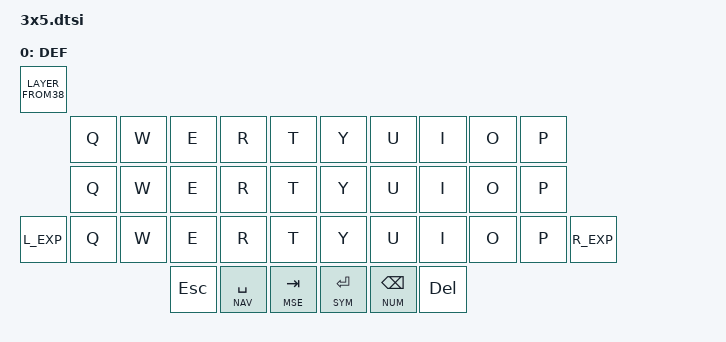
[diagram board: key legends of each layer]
#include <behaviors.dtsi>
#include <dt-bindings/zmk/keys.h>
#include <dt-bindings/zmk/bt.h>
// #include <dt-bindings/zmk/outputs.h>
// #include <dt-bindings/zmk/rgb.h>
// #include <dt-bindings/zmk/ext_power.h>
#include <behaviors/rgbled_widget.dtsi>

// Layer aliases
#define DEF 0
// #define NUM 1
// #define SYM 2
// #define NAV 3
// #define MSE 4

// totem 4 row additional keys
#define L_EXP ESC
#define R_EXP RET

// #include "shortcut.dtsi"
// #include "combos.dtsi"
// #include "mouse.dtsi"
// #include "behaviors.dtsi"
// #include "macros.dtsi"
/ {
    keymap {
        compatible = "zmk,keymap";

        default_layer {
            display-name = "DEF";
            bindings = <LAYER_FROM38( \
//           ╭──────────────┬──────────────┬──────────────┬──────────────┬──────────────╮   ╭──────────────┬──────────────┬──────────────┬──────────────┬──────────────╮
              &kp Q,         &kp W,         &kp E,         &kp R,         &kp T,             &kp Y,         &kp U,         &kp I,         &kp O,         &kp P, \
              &kp Q,         &kp W,         &kp E,         &kp R,         &kp T,             &kp Y,         &kp U,         &kp I,         &kp O,         &kp P, \
&kp L_EXP,    &kp Q,         &kp W,         &kp E,         &kp R,         &kp T,             &kp Y,         &kp U,         &kp I,         &kp O,         &kp P,         &kp R_EXP, \
                                            &kp ESC,       &lt NAV SPACE, &lt MSE TAB,       &lt SYM RET,   &lt NUM BSPC,  &kp DEL \
//                                         ╰─────────────┴──────────────┴──────────────╯    ╰──────────────┴──────────────┴──────────────╯
            )>;
        };
    };
};
